# tviibh16m register map
Vendor: Infineon Technologies; Series: TVIIBH16M; File version: 1.0
CPU: CM7 r0p1, little endian, MPU, FPU, double-precision FPU, I-cache, D-cache, VTOR, ITCM, DTCM, 3 interrupt priority bits, 16 interrupts
Registers are 32-bit, read-write, reset 0x0 unless marked. A register's access mark holds for its fields unless they carry their own. Offsets are from the block's base; [hi:lo] are bit positions; {n}, {i} and the like mark numbered series; 'fields as' and 'values as' point back to an identical list; <NAME> marks a mode.

## FLEXRAY0 (part 3 of 3) — FlexRay Bus Interface
Base 0x40560000
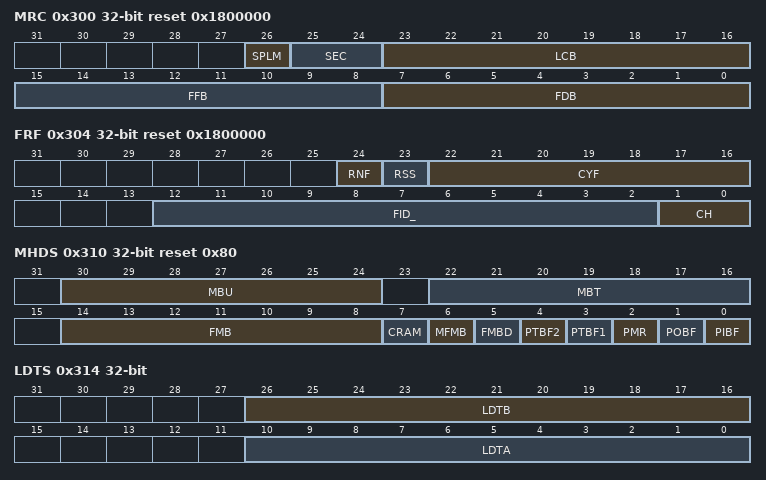
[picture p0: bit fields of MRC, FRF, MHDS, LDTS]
0x300 MRC reset 0x1800000 — Message RAM Configuration
  [26] SPLM — Sync Frame Payload Multiplex This bit is only evaluated if the node is configured as sync node (SUCC1.TXSY = '1') or for single slot mode operation (SUCC1.TSM = '1'). When this bit is set to '1' message buffers 0 and 1 are dedicated for sync frame transmission with different payload data on channel A and B. When this bit is set to '0', sync frames are transmitted from message buffer 0 with the same payload data on both channels. Note that the channel filter configuration for message buffer 0 resp. message buffer 1 has to be chosen accordingly. 1 = Both message buffers 0 and 1 are locked against reconfiguration 0 = Only message buffer 0 locked against reconfiguration
    0=MSG_BUFFER_0_LOCKED (N/A); 1=MSG_BUFFER_0_AND_1_LOCKED (N/A)
  [25:24] SEC — Secure Buffers Not evaluated when the CC is in DEFAULT_CONFIG or CONFIG state. For temporary unlocking see 5.12.4 Host Handling of Parity Errors. 00 = Reconfiguration of message buffers enabled with numbers < FFB enabled Exception: In nodes configured for sync frame transmission or for single slot mode operation message buffer 0 (and if SPLM = '1', also message buffer 1) is always locked 01 = Reconfiguration of message buffers with numbers < FDB and with numbers >= FFB locked and transmission of message buffers for static segment with numbers >= FDB disabled 10 = Reconfiguration of all message buffers locked 11 = Reconfiguration of all message buffers locked and transmission of message buffers for static segment with numbers => FDB disabled
    0=MSG_BUFFERS_LT_FFB_ENABLED (N/A); 1=MSG_BUFFERS_LT_FDB_ENABLED_AND_GT_FFB_LOCKED (N/A); 2=ALL_MSG_BUFFERS_LOCKED (N/A); 3=ALL_MSG_BUFFERS_LOCKED_AND_TXMN_OF_GT_FDB_LOCKED (N/A)
  [23:16] LCB — Last Configured Buffer 0...127 = Number of message buffers is LCB + 1 128 = No message buffer configured
  [15:8] FFB — First Buffer of FIFO 0 = All message buffers assigned to the FIFO 1...127 = Message buffers from FFB to LCB assigned to the FIFO 128 = No message buffer assigned to the FIFO
  [7:0] FDB
0x304 FRF reset 0x1800000 — FIFO Rejection Filter
  [24] RNF — Reject Null Frames If this bit is set, received null frames are not stored in the FIFO. 1 = Reject all null frames 0 = Null frames are stored in the FIFO
    0=NULL_FRAMES_FIFO_STORAGE_ENABLED (N/A); 1=NULL_FRAMES_FIFO_STORAGE_DISABLED (N/A)
  [23] RSS — Reject in Static Segment If this bit is set, the FIFO is used only for the dynamic segment. 1 = Reject messages in static segment 0 = FIFO also used for static segment
    0=FIFO_STATIC_SEGMENT_STORAGE_ENABLED (N/A); 1=FIFO_STATIC_SEGMENT_STORAGE_DISABLED (N/A)
  [22:16] CYF — Cycle Counter Filter The 7-bit cycle counter filter determines the cycle set to which frame ID and channel rejection filter are applied. In cycles not belonging to the cycle set specified by CYF[6:0], all frames are rejected. For details about the configuration of the cycle counter filter see [01]Section 5.7.2 Cycle Counter Filtering.
  [12:2] FID_ — Frame ID Filter Determines the frame ID to be rejected by the FIFO. With the additional configuration of register FRFM, the corresponding frame ID filter bits are ignored, which results in further rejected frame IDs. When FRFM.MFID[10:0] is zero, a frame ID filter value of zero means that no frame ID is rejected. 0...2047 = Frame ID filter values
  [1:0] CH — Channel Filter 11 = no reception 10 = receive only on channel A 01 = receive only on channel B 00 = receive on both channels
    0=RECEIVE_ON_BOTH_CHANNELS (N/A); 1=RECEIVE_ONLY_ON_CHANNEL_B (N/A); 2=RECEIVE_ONLY_ON_CHANNEL_A (N/A); 3=NO_RECEPTION (N/A)
0x308 FRFM — FIFO Rejection Filter Mask
  [12:2] MFID — Mask Frame ID Filter 1 = Ignore corresponding frame ID filter bit. 0 = Corresponding frame ID filter bit is used for rejection filtering
0x30C FCL reset 0x80 — FIFO Critical Level
  [7:0] CL — Critical Level When the receive FIFO fill level FSR.RFFL[7:0] is equal or greater than the critical level configured by CL[7:0], the receive FIFO critical level flag FSR.RFCL is set. If CL[7:0] is programmed to values > 128, bit FSR.RFCL is never set. When FSR.RFCL changes from '0' to 1' bit SIR.RFCL is set to '1', and if enabled, an interrupt is generated.
0x310 MHDS reset 0x80 — Message Handler Status
  [30:24] MBU ro — Message Buffer Updated Number of message buffer that was updated last by the CC. For this message buffer the respective ND and / or MBC flag in the NDAT1/2/3/4 registers and the MBSC1/2/3/4 registers are also set.
  [22:16] MBT ro — Message Buffer Transmitted Number of last successfully transmitted message buffer. If the message buffer is configured for single-shot mode, the respective TXR flag in the TXRQ1/2/3/4 registers was reset.
  [14:8] FMB ro — Faulty Message Buffer Parity error occurred when reading from the message buffer or when transferring data from Input Buffer or Transient Buffer 1,2 to the message buffer referenced by FMB[6:0]. Value only valid when one of the flags PIBF, PMR, PTBF1, PTBF2, and flag FMBD is set. Is not updated while flag FMBD is set.
  [7] CRAM ro — Clear all internal RAM's Signals that execution of the CHI command CLEAR_RAMS is ongoing (all bits of all internal RAM blocks are written to '0'). The bit is set by hard reset or by CHI command CLEAR_RAMS. 1 = Execution of the CHI command CLEAR_RAMS ongoing 0 = No execution of the CHI command CLEAR_RAMS
    0=CLEAR_RAMS_NOT_IN_PROGRESS (N/A); 1=CLEAR_RAMS_IN_PROGRESS (N/A)
  [6] MFMB write-1-clears — Multiple Faulty Message Buffers detected 1 = Another faulty message buffer was detected while flag FMBD is set 0 = No additional faulty message buffer
    0=NO_ADDITIONAL_FAULTY_MSG_BUFFER (N/A); 1=ADDITIONAL_FAULTY_MSG_BUFFER_ERROR (N/A)
  [5] FMBD write-1-clears — Faulty Message Buffer Detected 1 = Message buffer referenced by FMB[6:0] holds faulty data due to a parity error 0 = No faulty message buffer
    0=NO_FAULTY_MSG_BUFFER (N/A); 1=FAULTY_MSG_BUFFER_ERROR (N/A)
  [4] PTBF2 write-1-clears — Parity Error Transient Buffer RAM B 1 = Parity error occurred when reading Transient Buffer RAM B 0 = No parity error
    0=NO_PARITY_ERROR (N/A); 1=PARITY_ERROR_IN_TRAN_BUF_RAM_B (N/A)
  [3] PTBF1 write-1-clears — Parity Error Transient Buffer RAM A 1 = Parity error occurred when reading Transient Buffer RAM A 0 = No parity error
    0=NO_PARITY_ERROR (N/A); 1=PARITY_ERROR_IN_TRAN_BUF_RAM_A (N/A)
  [2] PMR write-1-clears — Parity Error Message RAM 1 = Parity error occurred when reading the Message RAM 0 = No parity error
    0=NO_PARITY_ERROR (N/A); 1=PARITY_ERROR_IN_MSG_RAM (N/A)
  [1] POBF write-1-clears — Parity Error Output Buffer RAM 1,2 1 = Parity error occurred when reading Output Buffer RAM 1,2 0 = No parity error
    0=NO_PARITY_ERROR (N/A); 1=PARITY_ERROR_IN_OBF_RAM_1_2 (N/A)
  [0] PIBF write-1-clears — Parity Error Input Buffer RAM 1,2 1 = Parity error occurred when reading Input Buffer RAM 1,2 0 = No parity error
    0=NO_PARITY_ERROR (N/A); 1=PARITY_ERROR_IN_IBF_RAM_1_2 (N/A)
0x314 LDTS ro — Last Dynamic Transmit Slot
  [26:16] LDTB — Last Dynamic Transmission Channel B Value of vSlotCounter[B] at the time of the last frame transmission on channel B in the dynamic segment of this node. It is updated at the end of the dynamic segment and is reset to zero if no frame was transmitted during the dynamic segment.
  [10:0] LDTA — Last Dynamic Transmission Channel A Value of vSlotCounter[A] at the time of the last frame transmission on channel A in the dynamic segment of this node. It is updated at the end of the dynamic segment and is reset to zero if no frame was transmitted during the dynamic segment.
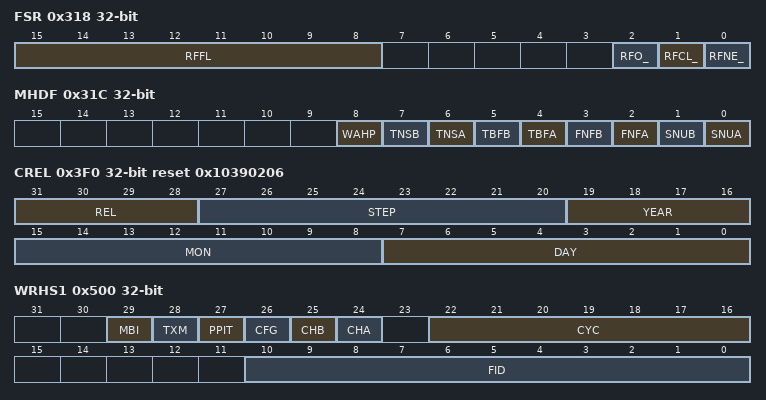
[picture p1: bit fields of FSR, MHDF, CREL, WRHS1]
0x318 FSR ro — FIFO Status Register
  [15:8] RFFL — Receive FIFO Fill Level Number of FIFO buffers filled with new data not yet read by the Host. Maximum value is 128.
  [2] RFO_ — Receive FIFO Overrun The flag is set by the CC when a receive FIFO overrun is detected. When a receive FIFO overrun occurs, the oldest message is overwritten with the actual received message. In addition, interrupt flag EIR.RFO is set.The flag is cleared by the next FIFO read access issued by the Host. 1 = A receive FIFO overrun has been detected 0 = No receive FIFO overrun detected
    0=RX_FIFO_NO_OVERRUN (N/A); 1=RX_FIFO_OVERRUN (N/A)
  [1] RFCL_ — Receive FIFO Critical Level This flag is set when the receive FIFO fill level RFFL[7:0] is equal or greater than the critical level as configured by FCL.CL[7:0]. The flag is cleared by the CC as soon as RFFL[7:0] drops below FCL.CL[7:0]. When RFCL changes from '0' to '1' bit SIR.RFCL is set to '1', and if enabled, an interrupt is generated. 1 = Receive FIFO critical level reached 0 = Receive FIFO below critical level
    0=RX_FIFO_LT_CRITICAL_LEVEL (N/A); 1=RX_FIFO_CRITICAL_LEVEL (N/A)
  [0] RFNE_ — Receive FIFO Not Empty This flag is set by the CC when a received valid frame (data or null frame depending on rejection mask) was stored in the FIFO. In addition, interrupt flag SIR.RFNE is set. The bit is reset after the Host has read all message from the FIFO. 1 = Receive FIFO is not empty 0 = Receive FIFO is empty
    0=RX_FIFO_EMPTY (N/A); 1=RX_FIFO_NOT_EMPTY (N/A)
0x31C MHDF — Message Handler Constraints Flags
  [8] WAHP — Write Attempt to Header Partition Outside DEFAULT_CONFIG and CONFIG state this flag is set by the CC when the message handler tries to write message data into the header partition of the Message RAM due to faulty configuration of a message buffer. The write attempt is not executed, to protect the header partition from unintended write accesses. 1 = Write attempt to header partition 0 = No write attempt to header partition
    0=HEADER_PARTITION_NO_WRITE (N/A); 1=HEADER_PARTITION_WRITE (N/A)
  [7] TNSB — Transmission Not Started Channel B This flag is set by the CC when the Message Handler was not ready to start a scheduled transmission on channel B at the action point of the configured slot. 1 = Transmission not started on channel B 0 = No transmission not started on channel B
    0=NO_CH_B_TXMN_NOT_STARTED (N/A); 1=CH_B_TXMN_NOT_STARTED (N/A)
  [6] TNSA — Transmission Not Started Channel A This flag is set by the CC when the Message Handler was not ready to start a scheduled transmission on channel A at the action point of the configured slot. 1 = Transmission not started on channel A 0 = No transmission not started on channel A
    0=NO_CH_A_TXMN_NOT_STARTED (N/A); 1=CH_A_TXMN_NOT_STARTED (N/A)
  [5] TBFB — Transient Buffer Access Failure B This flag is set by the CC when a read or write access to TBF B requested by PRT B could not complete within the available time. 1 = TBF B access failure 0 = No TBF B access failure
    0=TBF_CH_B_ACCESS_NOT_FAILED (N/A); 1=TBF_CH_B_ACCESS_FAILED (N/A)
  [4] TBFA — Transient Buffer Access Failure A This flag is set by the CC when a read or write access to TBF A requested by PRT A could not complete within the available time. 1 = TBF A access failure 0 = No TBF A access failure
    0=TBF_CH_A_ACCESS_NOT_FAILED (N/A); 1=TBF_CH_A_ACCESS_FAILED (N/A)
  [3] FNFB — Find Sequence Not Finished Channel B This flag is set by the CC when the Message Handler, due to overload condition, was not able to finish a find sequence (scan of Message RAM for matching message buffer) with respect to channel B. 1 = Find sequence not finished for channel B 0 = No find sequence not finished for channel B
    0=NO_CH_B_FIND_SEQ_NOT_FINISHED (N/A); 1=CH_B_FIND_SEQ_NOT_FINISHED (N/A)
  [2] FNFA — Find Sequence Not Finished Channel A This flag is set by the CC when the Message Handler, due to overload condition, was not able to finish a find sequence (scan of Message RAM for matching message buffer) with respect to channel A. 1 = Find sequence not finished for channel A 0 = No find sequence not finished for channel A
    0=NO_CH_A_FIND_SEQ_NOT_FINISHED (N/A); 1=CH_A_FIND_SEQ_NOT_FINISHED (N/A)
  [1] SNUB — Status Not Updated Channel B This flag is set by the CC when the Message Handler, due to overload condition, was not able to update a message buffer's status MBS with respect to channel B. 1 = MBS for channel B not updated 0 = No overload condition occurred when updating MBS for channel B
    0=MBS_FOR_CH_B_UPDATED (N/A); 1=MBS_FOR_CH_B_NOT_UPDATED (N/A)
  [0] SNUA — Status Not Updated Channel A This flag is set by the CC when the Message Handler, due to overload condition, was not able to update a message buffer's status MBS with respect to channel A. 1 = MBS for channel A not updated 0 = No overload condition occurred when updating MBS for channel A
    0=MBS_FOR_CH_A_UPDATED (N/A); 1=MBS_FOR_CH_A_NOT_UPDATED (N/A)
{0x31C+4i} TXRQ{i} ro (i=1..4) — Transmission Request {i}
  [31:0] TXR — Transmission Request TRX[{32i-1}:{32i-32}] If the flag is set, the respective message buffer is ready for transmission respectively transmission of this message buffer is in progress. In single-shot mode the flags are reset after transmission has completed.
{0x32C+4i} NDAT{i} ro (i=1..4) — New Data {i}
  [31:0] ND — New Data ND[{32i-1}:{32i-32}] The flags are set when a valid received data frame matches the message buffer's filter configuration, independent of the payload length received or the payload length configured for that message buffer. The flags are not set after reception of null frames except for message buffers belonging to the receive FIFO. An ND flag is reset when the header section of the corresponding message buffer is reconfigured or when the data section has been transferred to the Output Buffer.
{0x33C+4i} MBSC{i} ro (i=1..4) — Message Buffer Status Changed {i}
  [31:0] MBC — Message Buffer Status Changed MBC[{32i-1}:{32i-32}] An MBC flag is set whenever the Message Handler changes one of the status flags VFRA, VFRB, SEOA, SEOB, CEOA, CEOB, SVOA, SVOB, TCIA, TCIB, ESA, ESB, MLST, FTA, FTB in the header section (see 4.11.5 Message Buffer Status (MBS) and 5.12.1 Header Partition, header 4) of the respective message buffer. An MBC flag is reset when the header section of the corresponding message buffer is reconfigured or when it has been transferred to the Output Buffer.
0x3F0 CREL ro reset 0x10390206 — Core Release Register
  [31:28] REL — Core Release One digit, BCD-coded. Table 5: Coding for releases
  [27:20] STEP — Step of Core Release Two digits, BCD-coded.
  [19:16] YEAR — Design Time Stamp, Year One digit, BCD-coded.
  [15:8] MON — Design Time Stamp, Month Two digits, BCD-coded.
  [7:0] DAY — Design Time Stamp, Day Two digits, BCD-coded.
0x3F4 ENDN ro reset 0x87654321 — Endian Register
  [31:0] ETV — Endianness Test Value The endianness test value is 0x87654321.
{0x400+4i} WRDS[{i}] (i=0..63) — Write Data Section [1...64]
  [31:0] MD — Message Data MD[7:0] = DW2n-1, byte4n-4 MD[15:8] = DW2n-1, byte4n-3 MD[23:16] = DW2n, byte4n-2 MD[31:24] = DW2n, byte4n-1
0x500 WRHS1 — Write Header Section 1
  [29] MBI — Message Buffer Interrupt This bit enables the receive / transmit interrupt for the corresponding message buffer. After a dedicated receive buffer has been updated by the Message Handler, flag SIR.RXI and /or SIR.MBSI are set. After a transmission has completed flag SIR.TXI is set. 1 = The corresponding message buffer interrupt is enabled 0 = The corresponding message buffer interrupt is disabled
    0=MSG_BUFF_INTR_DISABLED (N/A); 1=MSG_BUFF_INTR_ENABLED (N/A)
  [28] TXM — Transmission Mode This bit is used to select the transmission mode (see [01]Section 5.8.3 Transmit Buffers). 1 = Single-shot mode 0 = Continuous mode
    0=CONTINUOUS_MODE (N/A); 1=SINGLE_SHOT_MODE (N/A)
  [27] PPIT — Payload Preamble Indicator Transmit This bit is used to control the state of the Payload Preamble Indicator in transmit frames. If the bit is set in a static message buffer, the respective message buffer holds network management information. If the bit is set in a dynamic message buffer the first two bytes of the payload segment may be used for message ID filtering by the receiver. Message ID filtering of received FlexRay frames is not supported by the E-Ray module, but can be done by the Host. 1 = Payload Preamble Indicator set 0 = Payload Preamble Indicator not set
    0=PAYLOAD_PREAMBLE_NOT_SET (N/A); 1=PAYLOAD_PREAMBLE_SET (N/A)
  [26] CFG — Message Buffer Direction Configuration Bit This bit is used to configure the corresponding buffer as transmit buffer or as receive buffer. For message buffers belonging to the receive FIFO the bit is not evaluated. 1 = The corresponding buffer is configured as Transmit Buffer 0 = The corresponding buffer is configured as Receive Buffer
    0=RX_BUFF (N/A); 1=TX_BUFF (N/A)
  [25] CHB — Channel Filter Control B The 2-bit channel filtering field associated with each buffer serves as a filter for receive buffers, and as a control field for transmit buffers. Note: If a message buffer is configured for the dynamic segment and both bits of the channel filtering field are set to '1', no frames are transmitted resp. received frames are ignored (same function as CHA = CHB = '0')
    0=CH_B_DISABLED (N/A); 1=CH_B_ENABLED (N/A)
  [24] CHA — Channel Filter Control A The 2-bit channel filtering field associated with each buffer serves as a filter for receive buffers, and as a control field for transmit buffers. Note: If a message buffer is configured for the dynamic segment and both bits of the channel filtering field are set to '1', no frames are transmitted resp. received frames are ignored (same function as CHA = CHB = '0')
    0=CH_A_DISABLED (N/A); 1=CH_A_ENABLED (N/A)
  [22:16] CYC — Cycle Code The 7-bit cycle code determines the cycle set used for cycle counter filtering. For details about the configuration of the cycle code see [01]Section 5.7.2 Cycle Counter Filtering. CHA, CHB Channel Filter Control The 2-bit channel filtering field associated with each buffer serves as a filter for receive buffers, and as a control field for transmit buffers. CHA CHB. Transmit Buffer transmit frame on Receive Buffer store frame received from 1 1 both channels static segment only) channel A or B store first semantically valid frame, static segment only) 1 0 channel A channel A 0 1 channel B channel B 0 0 no transmission ignore frame
  [10:0] FID — Frame ID Frame ID of the selected message buffer. The frame ID defines the slot number for transmission reception of the respective message. Message buffers with frame ID = '0' are considered as not valid.
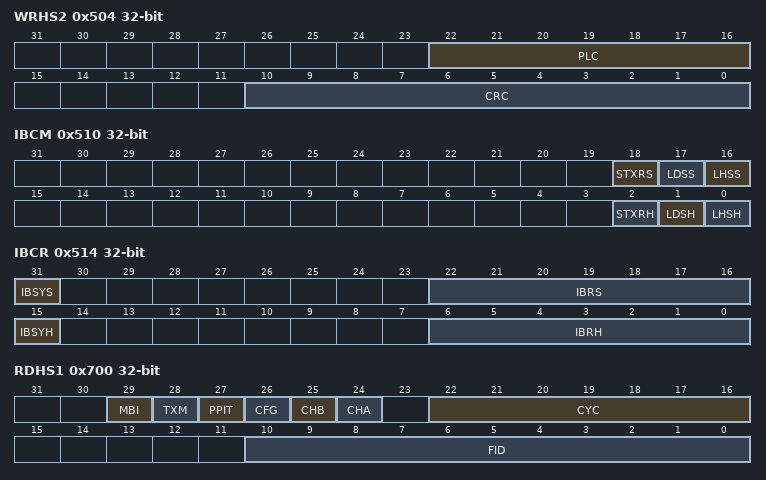
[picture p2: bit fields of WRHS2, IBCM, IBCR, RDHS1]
0x504 WRHS2 — Write Header Section 2
  [22:16] PLC — Payload Length Configured Length of data section (number of 2-byte words) as configured by the Host. During static segment the static frame payload length as configured by MHDC.SFDL[6:0] defines the payload length for all static frames. If the payload length configured by PLC[6:0] is shorter than this value padding bytes are inserted to ensure that frames have proper physical length. The padding pattern is logical zero (see also Section 5.8.3 Transmit Buffers).
  [10:0] CRC — Header CRC (vRF!Header!HeaderCRC) Receive Buffer: Configuration not required Transmit Buffer: Header CRC calculated and configured by the Host For calculation of the header CRC the payload length of the frame send on the bus has to be considered. In static segment the payload length of all frames is configured by MHDC.SFDL[6:0].
0x508 WRHS3 — Write Header Section 3
  [10:0] DP — Data Pointer Pointer to the first 32-bit word of the data section of the addressed message buffer in the Message RAM.
0x510 IBCM — Input Buffer Command Mask
  [18] STXRS ro — Set Transmission Request Shadow 1 = Set TXR flag, transmit buffer released for transmission (operation ongoing or finished) 0 = Reset TXR flag
    0=TXR_FLAG_RESET (N/A); 1=TXR_FLAG_SET (N/A)
  [17] LDSS ro — Load Data Section Shadow 1 = Data section selected for transfer from Input Buffer to the Message RAM transfer ongoing or finished) 0 = Data section is not updated
    0=DATA_SECTION_NOT_UPDATED (N/A); 1=DATA_SECTION_UPDATED (N/A)
  [16] LHSS ro — Load Header Section Shadow 1 = Header section selected for transfer from Input Buffer to the Message RAM transfer ongoing or finished) 0 = Header section is not updated
    0=HEADER_SECTION_NOT_UPDATED (N/A); 1=HEADER_SECTION_UPDATED (N/A)
  [2] STXRH — Set Transmission Request Host If this bit is set to '1', the TXR flag for the selected message buffer is set in the TXRQ1/2/3/4 registers to release the message buffer for transmission. In single-shot mode the flag is cleared by the CC after transmission has completed. TXR is evaluated for transmit buffers only. 1 = Set TXR flag, transmit buffer released for transmission 0 = Reset TXR flag
    0=TXR_FLAG_RESET (N/A); 1=TXR_FLAG_SET (N/A)
  [1] LDSH — Load Data Section Host 1 = Data section selected for transfer from Input Buffer to the Message RAM 0 = Data section is not updated
    values as LDSS
  [0] LHSH — Load Header Section Host 1 = Header section selected for transfer from Input Buffer to the Message RAM 0 = Header section is not updated
    values as LHSS
0x514 IBCR — Input Buffer Command Request
  [31] IBSYS ro — Input Buffer Busy Shadow Set to '1' after writing IBRH[6:0]. When the transfer between IBF Shadow and the Message RAM has completed, IBSYS is set back to '0'. 1 = Transfer between IBF Shadow and Message RAM in progress 0 = Transfer between IBF Shadow and Message RAM completed
    0=TXFR_IBF2MSRAM_COMPLETE (N/A); 1=TXFR_IBF2MSRAM_IN_PROGRESS (N/A)
  [22:16] IBRS ro — Input Buffer Request Shadow Number of the target message buffer actually updated / lately updated. Valid values are 0x00 to 0x7F (0...127).
  [15] IBSYH ro — Input Buffer Busy Host Set to '1' by writing IBRH[6:0] while IBSYS is still '1'. After the ongoing transfer between IBF Shadow and the Message RAM has completed, the IBSYH is set back to '0'. 1 = Request while transfer between IBF Shadow and Message RAM in progress 0 = No request pending
    0=REQUEST_NOT_PENDING (N/A); 1=REQUEST_IN_PROGRESS (N/A)
  [6:0] IBRH — Input Buffer Request Host Selects the target message buffer in the Message RAM for data transfer from Input Buffer. Valid values are 0x00 to 0x7F (0...127).
{0x600+4i} RDDS[{i}] (i=0..63) ro — Read Data Section [1...64]
  fields as WRDS[0]
0x700 RDHS1 ro — Read Header Section 1
  [29] MBI — Message Buffer Interrupt
  [28] TXM — Transmission Mode
  [27] PPIT — Payload Preamble Indicator Transmit
  [26] CFG — Message Buffer Direction Configuration Bit
  [25] CHB — Channel Filter Control B
  [24] CHA — Channel Filter Control A
  [22:16] CYC — Cycle Code
  [10:0] FID — Frame ID
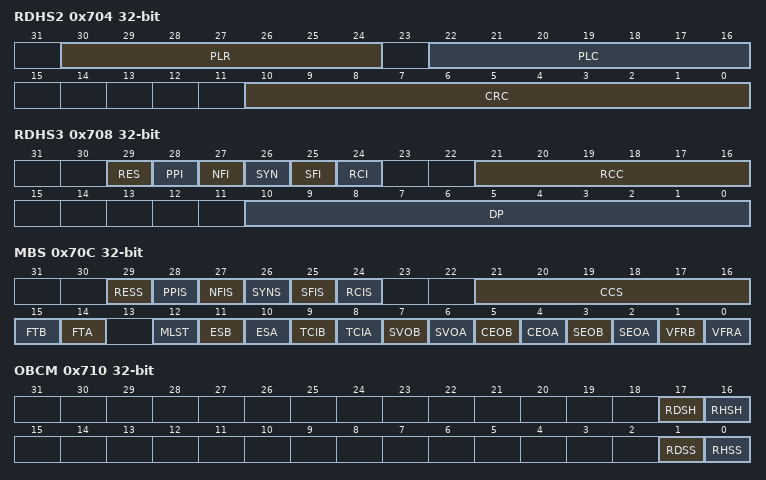
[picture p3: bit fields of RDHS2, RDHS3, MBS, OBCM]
0x704 RDHS2 ro — Read Header Section 2
  [30:24] PLR — Payload Length Received (vRF!Header!Length) Payload length value updated from received data frames (exception: if message buffer belongs to the receive FIFO PLR[6:0] is also updated from received null frames) When a message is stored into a message buffer the following behaviour with respect to payload length received and payload length configured is implemented: PLR[6:0] > PLC[6:0]: The payload data stored in the message buffer is truncated to the payload length configured if PLC[6:0] even or else truncated to PLC[6:0] + 1. PLR[6:0] <= PLC[6:0]: The received payload data is stored into the message buffers data section. The remaining data bytes of the data section as configured by PLC[6:0] are filled with undefined data PLR[6:0] = zero: The message buffer's data section is filled with undefined data PLC[6:0] = zero: Message buffer has no data section configured. No data is stored into the message buffer's data section.
  [22:16] PLC — Payload Length Configured Length of data section (number of 2-byte words) as configured by the Host.
  [10:0] CRC — Header CRC (vRF!Header!HeaderCRC) Receive Buffer: Header CRC updated from received data frames Transmit Buffer: Header CRC calculated and configured by the Host
0x708 RDHS3 ro — Read Header Section 3
  [29] RES
  [28] PPI — Payload Preamble Indicator (vRF!Header!PPIndicator) The payload preamble indicator defines whether a network management vector or message ID is contained within the payload segment of the received frame. 1 = Static segment: Network management vector in the first part of the payload Dynamic segment:Message ID in the first part of the payload 0 = The payload segment of the received frame does not contain a network management vector nor a message ID
    0=PAYLOAD_SEGMENT_HAS_NO_NMV_MID (N/A); 1=PAYLOAD_SEGMENT_WITH_NMV_MID (N/A)
  [27] NFI — Null Frame Indicator (vRF!Header!NFIndicator) Is set to '1' after storage of the first received data frame. 1 = At least one data frame has been stored into the respective message buffer 0 = Up to now no data frame has been stored into the respective message buffer
    0=DATA_FRAME_NOT_STORED (N/A); 1=DATA_FRAME_STORED (N/A)
  [26] SYN — Sync Frame Indicator (vRF!Header!SyFIndicator) A sync frame is marked by the sync frame indicator. 1 = The received frame is a sync frame 0 = The received frame is not a sync frame
    0=RXD_FRAME_NOT_SYNC_FRAME (N/A); 1=RXD_FRAME_SYNC_FRAME (N/A)
  [25] SFI — Startup Frame Indicator (vRF!Header!SuFIndicator) A startup frame is marked by the startup frame indicator. 1 = The received frame is a startup frame 0 = The received frame is not a startup frame
    0=RXD_FRAME_NOT_STARTUP_FRAME (N/A); 1=RXD_FRAME_STARTUP_FRAME (N/A)
  [24] RCI — Received on Channel Indicator (vSS!Channel) Indicates the channel from which the received data frame was taken to update the respective receive buffer. 1 = Frame received on channel A 0 = Frame received on channel B
    0=CH_B_FRAME_RECEIVED (N/A); 1=CH_A_FRAME_RECEIVED (N/A)
  [21:16] RCC — Receive Cycle Count (vRF!Header!CycleCount) Cycle counter value updated from received data frame.
  [10:0] DP — Data Pointer Pointer to the first 32-bit word of the data section of the addressed message buffer in the Message RAM.
0x70C MBS ro — Message Buffer Status
  [29] RESS
  [28] PPIS — Payload Preamble Indicator Status (vRF!Header!PPIndicator) The payload preamble indicator defines whether a network management vector or message ID is contained within the payload segment of the received frame. 1 = Static segment: Network management vector at the beginning of the payload Dynamic segment: Message ID at the beginning of the payload 0 = The payload segment of the received frame does not contain a network management vector or a message ID
    values as RDHS3.PPI
  [27] NFIS — Null Frame Indicator Status (vRF!Header!NFIndicator) If set to '0' the payload segment of the received frame contains no usable data. 1 = Received frame is not a null frame 0 = Received frame is a null frame
    0=NULL_FRAME_RECEIVED (N/A); 1=NO_NULL_FRAME_RECEIVED (N/A)
  [26] SYNS — Sync Frame Indicator Status (vRF!Header!SyFIndicator) A sync frame is marked by the sync frame indicator. 1 = The received frame is a sync frame 0 = No sync frame received
    0=NO_SYNC_FRAME_RECEIVED (N/A); 1=SYNC_FRAME_RECEIVED (N/A)
  [25] SFIS — Startup Frame Indicator Status (vRF!Header!SuFIndicator) A startup frame is marked by the startup frame indicator. 1 = The received frame is a startup frame 0 = No startup frame received
    0=NO_STARTUP_FRAME_RECEIVED (N/A); 1=STARTUP_FRAME_RECEIVED (N/A)
  [24] RCIS — Received on Channel Indicator Status (vSS!Channel) Indicates the channel on which the frame was received. 1 = Frame received on channel A 0 = Frame received on channel B
    0=CH_B_FRAME_RECEIVED (N/A); 1=CH_A_FRAME_RECEIVED (N/A)
  [21:16] CCS — Cycle Count Status Actual cycle count when status was updated. For receive buffers (CFG = '0') the following status bits are updated from both valid data and null frames. If no valid frame was received, the previous value is maintained. For transmit buffers the flags have no meaning and should be ignored.
  [15] FTB — Frame Transmitted on Channel B Indicates that this node has transmitted a data frame in the configured slot on channel B. 1 = Data frame transmitted on channel B 0 = No data frame transmitted on channel B
    0=DATA_FRAME_NOT_TXD_ON_CH_B (N/A); 1=DATA_FRAME_TXD_ON_CH_B (N/A)
  [14] FTA — Frame Transmitted on Channel A Indicates that this node has transmitted a data frame in the configured slot on channel A. 1 = Data frame transmitted on channel A 0 = No data frame transmitted on channel A
    0=DATA_FRAME_NOT_TXD_ON_CH_A (N/A); 1=DATA_FRAME_TXD_ON_CH_A (N/A)
  [12] MLST — Message Lost The flag is set in case the Host did not read the message before the message buffer was updated from a received data frame. Not affected by reception of null frames except for message buffers belonging to the receive FIFO. The flag is reset by a Host write to the message buffer via IBF or when a new message is stored into the message buffer after the message buffers ND flag was reset by reading out the message buffer via OBF. 1 = Unprocessed message was overwritten 0 = No message lost
    0=NO_MSG_LOST (N/A); 1=MSG_LOST (N/A)
  [11] ESB — Empty Slot Channel B In an empty slot there is no activity detected on the bus. The condition is checked in static and dynamic slots. 1 = No bus activity detected in the assigned slot on channel B 0 = Bus activity detected in the assigned slot on channel B
    0=CH_B_HAS_BUS_ACTIVITY (N/A); 1=CH_B_NO_BUS_ACTIVITY (N/A)
  [10] ESA — Empty Slot Channel A In an empty slot there is no activity detected on the bus. The condition is checked in static and dynamic slots. 1 = No bus activity detected in the assigned slot on channel A 0 = Bus activity detected in the assigned slot on channel A
    0=CH_A_HAS_BUS_ACTIVITY (N/A); 1=CH_A_NO_BUS_ACTIVITY (N/A)
  [9] TCIB — Transmission Conflict Indication Channel B (vSS!TxConflictB) A transmission conflict indication is set if a transmission conflict has occurred on channel B. 1 = Transmission conflict occurred on channel B 0 = No transmission conflict occurred on channel B
    0=CH_B_NO_TXMN_CONFLICT (N/A); 1=CH_B_HAS_TXMN_CONFLICT (N/A)
  [8] TCIA — Transmission Conflict Indication Channel A (vSS!TxConflictA) A transmission conflict indication is set if a transmission conflict has occurred on channel A. 1 = Transmission conflict occurred on channel A 0 = No transmission conflict occurred on channel A
    0=CH_A_NO_TXMN_CONFLICT (N/A); 1=CH_A_HAS_TXMN_CONFLICT (N/A)
  [7] SVOB — Slot Boundary Violation Observed on Channel B (vSS!BViolationB) A slot boundary violation (channel active at the start or at the end of the assigned slot) was observed on channel B. 1 = Slot boundary violation observed on channel B 0 = No slot boundary violation observed on channel B
    0=CH_B_NO_SLOT_BNDRY_VIOLATION (N/A); 1=CH_B_HAS_SLOT_BNDRY_VIOLATION (N/A)
  [6] SVOA — Slot Boundary Violation Observed on Channel A (vSS!BViolationA) A slot boundary violation (channel active at the start or at the end of the assigned slot) was observed on channel A. 1 = Slot boundary violation observed on channel A 0 = No slot boundary violation observed on channel A
    0=CH_A_NO_SLOT_BNDRY_VIOLATION (N/A); 1=CH_A_HAS_SLOT_BNDRY_VIOLATION (N/A)
  [5] CEOB — Content Error Observed on Channel B (vSS!ContentErrorB) A content error was observed in the assigned slot on channel B. 1 = Content error observed on channel B 0 = No content error observed on channel B
    0=CH_B_NO_CONTENT_ERROR (N/A); 1=CH_B_HAS_CONTENT_ERROR (N/A)
  [4] CEOA — Content Error Observed on Channel A (vSS!ContentErrorA) A content error was observed in the assigned slot on channel A. 1 = Content error observed on channel A 0 = No content error observed on channel A
    0=CH_A_NO_CONTENT_ERROR (N/A); 1=CH_A_HAS_CONTENT_ERROR (N/A)
  [3] SEOB — Syntax Error Observed on Channel B (vSS!SyntaxErrorB) A syntax error was observed in the assigned slot on channel B. 1 = Syntax error observed on channel B 0 = No syntax error observed on channel B
    0=CH_B_NO_SYNTAX_ERROR (N/A); 1=CH_B_HAS_SYNTAX_ERROR (N/A)
  [2] SEOA — Syntax Error Observed on Channel A (vSS!SyntaxErrorA) A syntax error was observed in the assigned slot on channel A. 1 = Syntax error observed on channel A 0 = No syntax error observed on channel A
    0=CH_A_NO_SYNTAX_ERROR (N/A); 1=CH_A_HAS_SYNTAX_ERROR (N/A)
  [1] VFRB — Valid Frame Received on Channel B (vSS!ValidFrameB) A valid frame indication is set if a valid frame was received on channel B. 1 = Valid frame received on channel B 0 = No valid frame received on channel B
    0=CH_B_NO_VALID_FRAME (N/A); 1=CH_B_WITH_VALID_FRAME (N/A)
  [0] VFRA — Valid Frame Received on Channel A (vSS!ValidFrameA) A valid frame indication is set if a valid frame was received on channel A. 1 = Valid frame received on channel A 0 = No valid frame received on channel A
    0=CH_A_NO_VALID_FRAME (N/A); 1=CH_A_WITH_VALID_FRAME (N/A)
0x710 OBCM — Output Buffer Command Mask
  [17] RDSH ro — Read Data Section Host 1 = Data section selected for transfer from Message RAM to Output Buffer 0 = Data section is not read
    0=DATA_SECTION_NOT_READ (N/A); 1=DATA_SECTION_FOR_MSRAM2OBF_TXFR (N/A)
  [16] RHSH ro — Read Header Section Host 1 = Header section selected for transfer from Message RAM to Output Buffer 0 = Header section is not read
    0=HEADER_SECTION_NOT_READ (N/A); 1=HEADER_SECTION_FOR_MSRAM2OBF_TXFR (N/A)
  [1] RDSS — Read Data Section Shadow 1 = Data section selected for transfer from Message RAM to Output Buffer 0 = Data section is not read
    values as RDSH
  [0] RHSS — Read Header Section Shadow 1 = Header section selected for transfer from Message RAM to Output Buffer 0 = Header section is not read
    values as RHSH
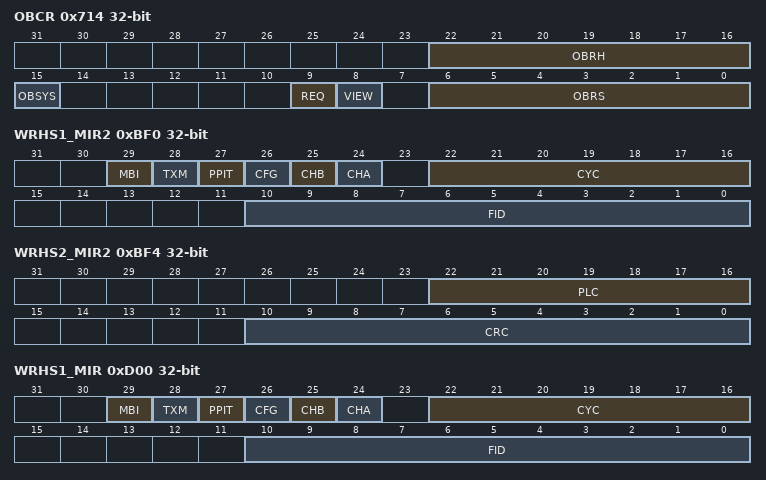
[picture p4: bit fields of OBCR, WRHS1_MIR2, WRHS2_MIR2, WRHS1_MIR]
0x714 OBCR — Output Buffer Command Request
  [22:16] OBRH ro — Output Buffer Request Host Number of message buffer currently accessible by the Host via RDHS[1...3], MBS, and RDDS[1...64]. By writing VIEW to '1' OBF Shadow and OBF Host are swapped and the transferred message buffer is accessible by the Host. Valid values are 0x00 to 0x7F (0...127).
  [15] OBSYS ro — Output Buffer Busy Shadow Set to '1' after setting bit REQ. When the transfer between the Message RAM and OBF Shadow has completed, OBSYS is set back to '0'. 1 = Transfer between Message RAM and OBF Shadow in progress 0 = No transfer in progress
    0=NO_TXFR_IN_PROGRESS (N/A); 1=TXFR_BTW_MSRAM_AND_OBFS (N/A)
  [9] REQ — Request Message RAM Transfer Requests transfer of message buffer addressed by OBRS[6:0] from Message RAM to OBF Shadow. Only writeable while OBSYS = '0'. 1 = Transfer to OBF Shadow requested 0 = No request
    0=NO_REQUEST (N/A); 1=TXFR_TO_OBFS_REQ (N/A)
  [8] VIEW — View Shadow Buffer Toggles between OBF Shadow and OBF Host. Only writeable while OBSYS = '0'. 1 = Swap OBF Shadow and OBF Host 0 = No action
    0=NO_ACTION (N/A); 1=SWP_OBFS_AND_OBFH (N/A)
  [6:0] OBRS — Output Buffer Request Shadow Number of source message buffer to be transferred from the Message RAM to OBF Shadow. Valid values are 0x00 to 0x7F (0...127). If the number of the first message buffer of the receive FIFO is written to this register the Message Handler transfers the message buffer addressed by the GET Index (GIDX, see [01]Section 5.10 FIFO Function) to OBF Shadow.
0xBF0 WRHS1_MIR2 — Write Header Section 1 (2nd mirror)
  fields as WRHS1
0xBF4 WRHS2_MIR2 — Write Header Section 2 (2nd mirror)
  fields as WRHS2
0xBF8 WRHS3_MIR2 — Write Header Section 3 (2nd mirror)
  fields as WRHS3
{0xC00+4i} WRDS_MIR[{i}] (i=0..63) — Write Data Section [1...64] (mirror)
  fields as WRDS[0]
0xD00 WRHS1_MIR — Write Header Section 1 (mirror)
  fields as WRHS1
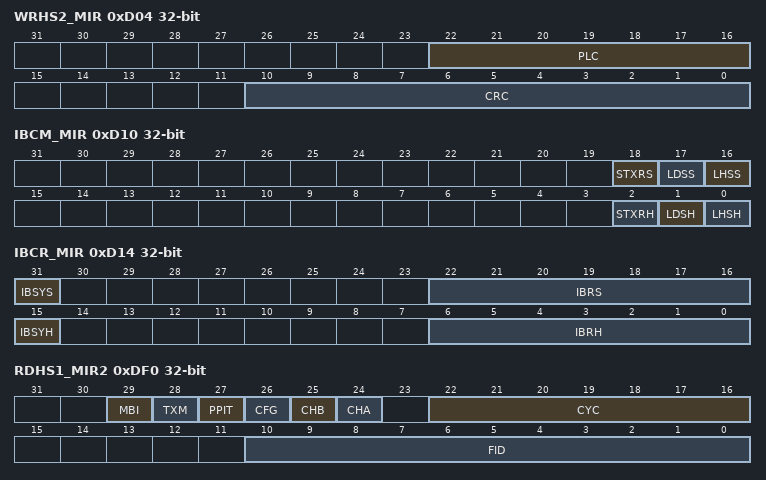
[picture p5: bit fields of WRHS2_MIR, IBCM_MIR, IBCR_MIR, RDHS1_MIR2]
0xD04 WRHS2_MIR — Write Header Section 2 (mirror)
  fields as WRHS2
0xD08 WRHS3_MIR — Write Header Section 3 (mirror)
  fields as WRHS3
0xD10 IBCM_MIR — Input Buffer Command Mask (mirror)
  fields as IBCM
0xD14 IBCR_MIR — Input Buffer Command Request (mirror)
  fields as IBCR
0xDF0 RDHS1_MIR2 ro — Read Header Section 1 (2nd mirror)
  fields as RDHS1
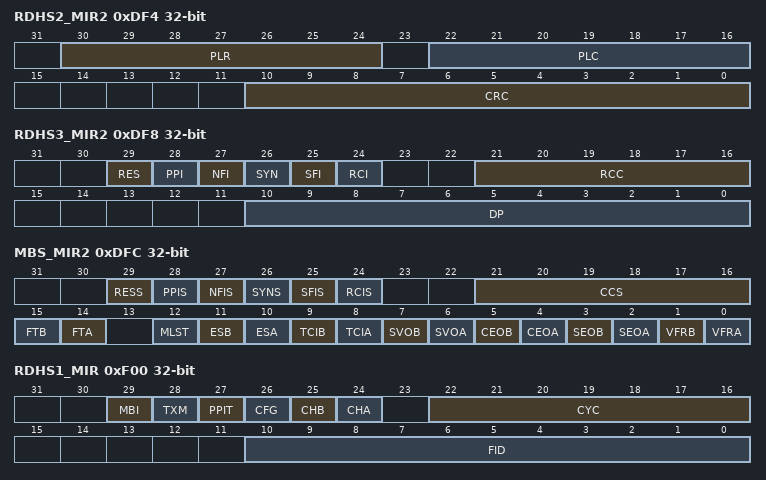
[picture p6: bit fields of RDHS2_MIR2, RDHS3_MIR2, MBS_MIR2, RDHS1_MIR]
0xDF4 RDHS2_MIR2 ro — Read Header Section 2 (2nd mirror)
  fields as RDHS2
0xDF8 RDHS3_MIR2 ro — Read Header Section 3 (2nd mirror)
  fields as RDHS3
0xDFC MBS_MIR2 ro — Message Buffer Status (2nd mirror)
  fields as MBS
{0xE00+4i} RDDS_MIR[{i}] (i=0..63) ro — Read Data Section [1...64] (mirror)
  fields as WRDS[0]
0xF00 RDHS1_MIR ro — Read Header Section 1 (mirror)
  fields as RDHS1
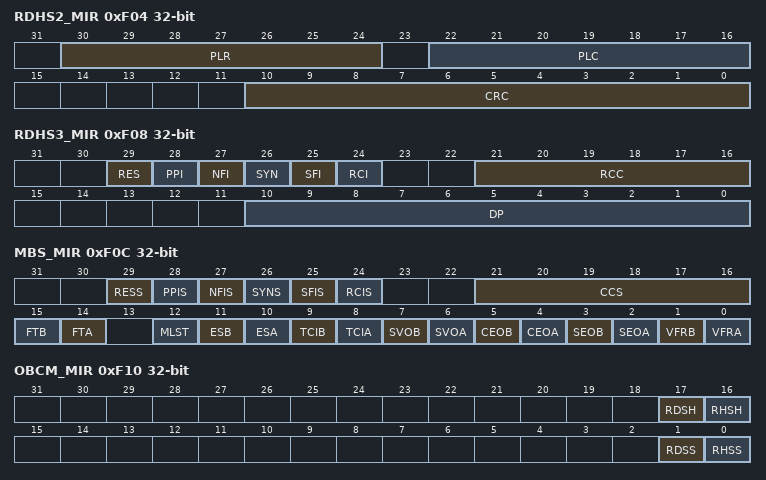
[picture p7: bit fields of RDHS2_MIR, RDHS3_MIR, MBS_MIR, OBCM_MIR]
0xF04 RDHS2_MIR ro — Read Header Section 2 (mirror)
  fields as RDHS2
0xF08 RDHS3_MIR ro — Read Header Section 3 (mirror)
  fields as RDHS3
0xF0C MBS_MIR ro — Message Buffer Status (mirror)
  fields as MBS
0xF10 OBCM_MIR — Output Buffer Command Mask (mirror)
  fields as OBCM
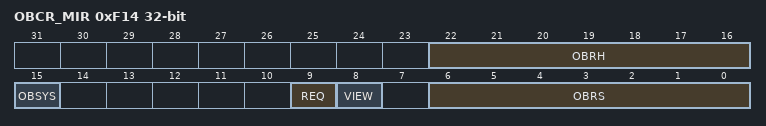
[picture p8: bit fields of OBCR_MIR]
0xF14 OBCR_MIR — Output Buffer Command Request (mirror)
  fields as OBCR
